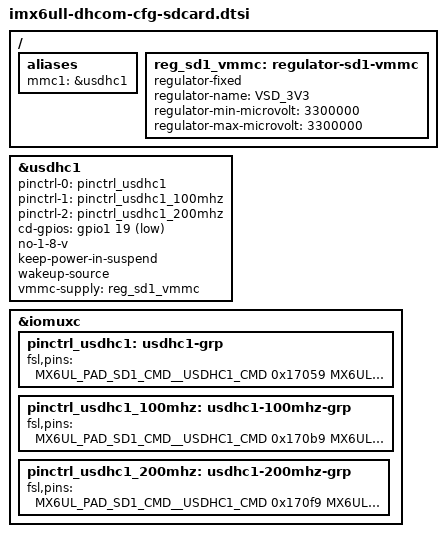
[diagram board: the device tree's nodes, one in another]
// SPDX-License-Identifier: (GPL-2.0-or-later)
/*
 * Copyright (C) 2018 DH electronics GmbH
 */

/*
 * Special configuration: sdcard
 *
 * Enabled:  uSD card (on module) or
 *           uSD/SD/MMC card interface (external) depends on hardware variant
 *           GPIO H and GPIO I will be available
 *           DHCOM UART2 will be available
 * Disabled: WiFi and BT
 */

/ {
	aliases {
		mmc1 = &usdhc1; /* Card interface should be mmc1 */
	};

	reg_sd1_vmmc: regulator-sd1-vmmc {
		compatible = "regulator-fixed";
		regulator-name = "VSD_3V3";
		regulator-min-microvolt = <3300000>;
		regulator-max-microvolt = <3300000>;
	};
};


/delete-node/ &brcmf; /* Delete wifi node of usdhc1 */
&usdhc1 { /* uSD card (on module) or uSD/SD/MMC card interface (external) */
	/delete-property/ non-removable;
	/delete-property/ mmc-pwrseq;
	/delete-property/ #address-cells;
	/delete-property/ #size-cells;

	pinctrl-names = "default", "state_100mhz", "state_200mhz";
	pinctrl-0 = <&pinctrl_usdhc1>;
	pinctrl-1 = <&pinctrl_usdhc1_100mhz>;
	pinctrl-2 = <&pinctrl_usdhc1_200mhz>;
	cd-gpios = <&gpio1 19 GPIO_ACTIVE_LOW>;
	no-1-8-v;
	keep-power-in-suspend;
	wakeup-source;
	vmmc-supply = <&reg_sd1_vmmc>;
	status = "okay";
};

&iomuxc {
	pinctrl_usdhc1: usdhc1-grp {
		fsl,pins = <
			MX6UL_PAD_SD1_CMD__USDHC1_CMD		0x17059
			MX6UL_PAD_SD1_CLK__USDHC1_CLK		0x10059
			MX6UL_PAD_SD1_DATA0__USDHC1_DATA0	0x17059
			MX6UL_PAD_SD1_DATA1__USDHC1_DATA1	0x17059
			MX6UL_PAD_SD1_DATA2__USDHC1_DATA2	0x17059
			MX6UL_PAD_SD1_DATA3__USDHC1_DATA3	0x17059
			MX6UL_PAD_UART1_RTS_B__GPIO1_IO19	0x120b0 /* SD1 CD */
		>;
	};

	pinctrl_usdhc1_100mhz: usdhc1-100mhz-grp {
		fsl,pins = <
			MX6UL_PAD_SD1_CMD__USDHC1_CMD		0x170b9
			MX6UL_PAD_SD1_CLK__USDHC1_CLK		0x100b9
			MX6UL_PAD_SD1_DATA0__USDHC1_DATA0	0x170b9
			MX6UL_PAD_SD1_DATA1__USDHC1_DATA1	0x170b9
			MX6UL_PAD_SD1_DATA2__USDHC1_DATA2	0x170b9
			MX6UL_PAD_SD1_DATA3__USDHC1_DATA3	0x170b9
			MX6UL_PAD_UART1_RTS_B__GPIO1_IO19	0x120b0 /* SD1 CD */

		>;
	};

	pinctrl_usdhc1_200mhz: usdhc1-200mhz-grp {
		fsl,pins = <
			MX6UL_PAD_SD1_CMD__USDHC1_CMD		0x170f9
			MX6UL_PAD_SD1_CLK__USDHC1_CLK		0x100f9
			MX6UL_PAD_SD1_DATA0__USDHC1_DATA0	0x170f9
			MX6UL_PAD_SD1_DATA1__USDHC1_DATA1	0x170f9
			MX6UL_PAD_SD1_DATA2__USDHC1_DATA2	0x170f9
			MX6UL_PAD_SD1_DATA3__USDHC1_DATA3	0x170f9
			MX6UL_PAD_UART1_RTS_B__GPIO1_IO19	0x120b0 /* SD1 CD */
		>;
	};
};
